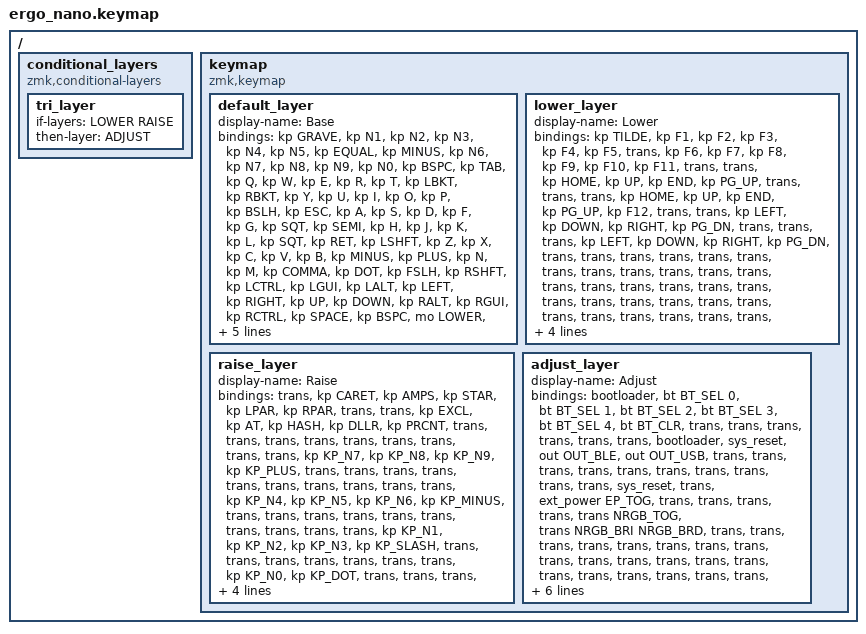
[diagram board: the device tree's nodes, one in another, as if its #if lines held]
#include <behaviors.dtsi>
#include <dt-bindings/zmk/keys.h>
#include <dt-bindings/zmk/bt.h>
#include <dt-bindings/zmk/outputs.h>
#include <dt-bindings/zmk/rgb.h>
#include <dt-bindings/keypaw/rgb_matrix.h>
#include <dt-bindings/zmk/ext_power.h>

#if defined(CONFIG_ZMK_STUDIO)
    #define KEY_STUDIO_UNLOCK &studio_unlock
#else
    #define KEY_STUDIO_UNLOCK &trans
#endif
#if defined(CONFIG_KEYPAW_RGB_MATRIX)
    #define NRGB_TOG &nano_rgb RGB_TOG 0
    #define NRGB_BRI &nano_rgb RGB_BRI 0
    #define NRGB_BRD &nano_rgb RGB_BRD 0
#else
    #define NRGB_TOG &trans
    #define NRGB_BRI &trans
    #define NRGB_BRD &trans
#endif

#define BASE   0
#define LOWER  1
#define RAISE  2
#define ADJUST 3

/ {
    // Tri-layer: activating LOWER and RAISE simultaneously triggers ADJUST
    conditional_layers {
        compatible = "zmk,conditional-layers";
        tri_layer {
            if-layers = <LOWER RAISE>;
            then-layer = <ADJUST>;
        };
    };

    keymap {
        compatible = "zmk,keymap";

        default_layer {
            display-name = "Base";
            bindings = <
                /* --- LEFT HAND --- */
                /* Num Row */
                &kp GRAVE  &kp N1     &kp N2    &kp N3    &kp N4     &kp N5    &kp EQUAL    &kp MINUS  &kp N6     &kp N7    &kp N8    &kp N9     &kp N0    &kp BSPC
                /* Top Row */
                &kp TAB    &kp Q      &kp W     &kp E     &kp R      &kp T     &kp LBKT     &kp RBKT   &kp Y      &kp U     &kp I     &kp O      &kp P     &kp BSLH
                /* Home Row */
                &kp ESC    &kp A      &kp S     &kp D     &kp F      &kp G     &kp SQT      &kp SEMI   &kp H      &kp J     &kp K     &kp L      &kp SQT   &kp RET
                /* Bottom Row */
                &kp LSHFT  &kp Z      &kp X     &kp C     &kp V      &kp B     &kp MINUS    &kp PLUS   &kp N      &kp M     &kp COMMA &kp DOT    &kp FSLH  &kp RSHFT
                /* Mod Row */
                &kp LCTRL  &kp LGUI   &kp LALT  &kp LEFT  &kp RIGHT                         &kp UP     &kp DOWN   &kp RALT  &kp RGUI  &kp RCTRL
                /* Thumbs & Encoder Button */
                &kp SPACE  &kp BSPC   &mo LOWER &kp DEL   &kp LALT   &kp C_MUTE             &kp RET    &kp SPACE  &mo RAISE &mo ADJUST &kp RGUI  &kp C_PP
            >;
            sensor-bindings = <&inc_dec_kp C_VOL_DN C_VOL_UP &inc_dec_kp PG_DN PG_UP>;
        };

        lower_layer {
            display-name = "Lower";
            bindings = <
                /* --- LEFT HAND --- */
                /* Num Row */
                &kp TILDE  &kp F1     &kp F2    &kp F3    &kp F4     &kp F5    &trans    &kp F6     &kp F7     &kp F8    &kp F9    &kp F10    &kp F11   &trans
                /* Top Row */
                &trans     &kp HOME   &kp UP    &kp END   &kp PG_UP  &trans    &trans    &trans     &kp HOME   &kp UP    &kp END   &kp PG_UP  &kp F12   &trans
                /* Home Row */
                &trans     &kp LEFT   &kp DOWN  &kp RIGHT &kp PG_DN  &trans    &trans    &trans     &kp LEFT   &kp DOWN  &kp RIGHT &kp PG_DN  &trans    &trans
                /* Bottom Row */
                &trans     &trans     &trans    &trans    &trans     &trans    &trans    &trans     &trans     &trans    &trans    &trans     &trans    &trans
                /* Mod Row */
                &trans     &trans     &trans    &trans    &trans                         &trans     &trans     &trans    &trans    &trans
                /* Thumbs & Encoder Button */
                &trans     &trans     &trans    &trans    &trans     &trans              &trans     &trans     &trans    &trans    &trans     &trans
            >;
            sensor-bindings = <&inc_dec_kp C_VOL_DN C_VOL_UP &inc_dec_kp PG_DN PG_UP>;
        };

        raise_layer {
            display-name = "Raise";
            bindings = <
                /* --- LEFT HAND --- */
                /* Num Row */
                &trans     &kp CARET  &kp AMPS  &kp STAR  &kp LPAR   &kp RPAR  &trans    &trans     &kp EXCL   &kp AT    &kp HASH  &kp DLLR   &kp PRCNT &trans 
                /* Top Row */
                &trans     &trans     &trans    &trans    &trans     &trans    &trans    &trans     &kp KP_N7  &kp KP_N8 &kp KP_N9 &kp KP_PLUS &trans   &trans
                /* Home Row */
                &trans     &trans     &trans    &trans    &trans     &trans    &trans    &trans     &kp KP_N4  &kp KP_N5 &kp KP_N6 &kp KP_MINUS &trans  &trans
                /* Bottom Row */
                &trans     &trans     &trans    &trans    &trans     &trans    &trans    &trans     &kp KP_N1  &kp KP_N2 &kp KP_N3 &kp KP_SLASH &trans  &trans
                /* Mod Row */
                &trans     &trans     &trans    &trans    &trans                                    &kp KP_N0  &kp KP_DOT &trans    &trans    &trans
                /* Thumbs & Encoder Button */
                &trans     &trans     &trans    &trans    &trans     &trans &trans     &trans     &trans    &trans    &trans     &trans
            >;
            sensor-bindings = <&inc_dec_kp C_VOL_DN C_VOL_UP &inc_dec_kp PG_DN PG_UP>;
        };

        adjust_layer {
            display-name = "Adjust";
            bindings = <
                /* --- LEFT HAND --- */
                /* Num Row */
                &bootloader &bt BT_SEL 0 &bt BT_SEL 1 &bt BT_SEL 2 &bt BT_SEL 3 &bt BT_SEL 4 &bt BT_CLR    &trans      &trans       &trans       &trans       &trans       &trans       &bootloader
                /* Top Row */
                &sys_reset  &out OUT_BLE &out OUT_USB &trans       &trans       &trans       &trans    &trans      &trans       &trans       &trans       &trans       &trans       &sys_reset
                /* Home Row */
                /* rgb_ug behaviors are replaced with RGB (keypaw,rgb-matrix behavior).
                 * RGB_EFF / HUI / HUD / SAI / SAD are not supported by the keypaw behavior's
                 * main control node — effect selection uses keypaw,rgb-matrix-selector nodes
                 * declared in the devicetree overlay instead. */
                &trans      &ext_power EP_TOG &trans  &trans       &trans       &trans       &trans   NRGB_TOG &trans NRGB_BRI NRGB_BRD &trans &trans &trans
                /* Bottom Row */
                &trans      &trans       &trans       &trans       &trans       &trans       &trans    &trans &trans &trans &trans &trans &trans &trans
                /* Mod Row */
                &trans      &trans       &trans       &trans       &trans                              &trans       &trans        &trans       &trans       &trans
                /* Thumbs & Encoder Button */
                KEY_STUDIO_UNLOCK &trans &trans       &trans       &trans       &trans             &trans      &trans       &trans        &trans       &trans       &trans
            >;
            sensor-bindings = <&inc_dec_kp C_VOL_DN C_VOL_UP &inc_dec_kp PG_DN PG_UP>;
        };
    };
};
